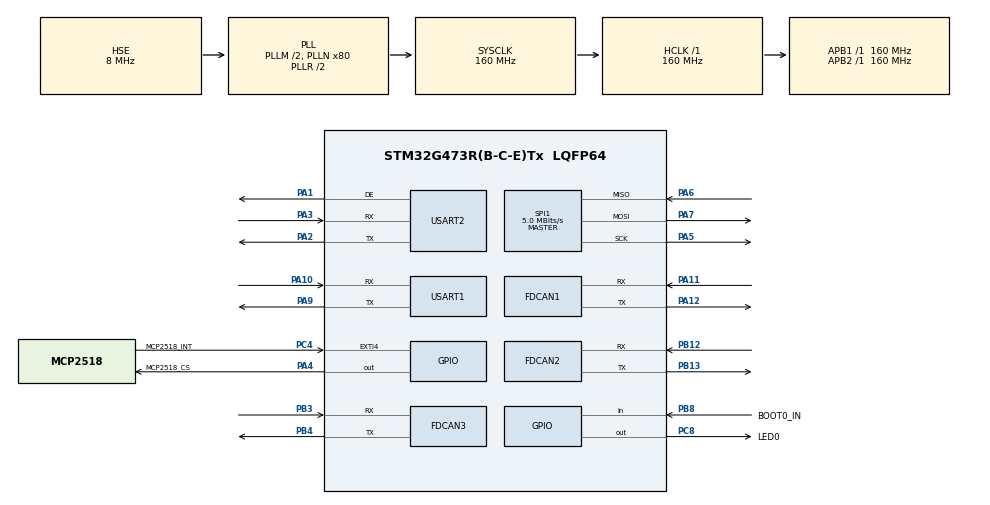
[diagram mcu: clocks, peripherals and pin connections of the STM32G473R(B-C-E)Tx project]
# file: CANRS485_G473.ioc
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FDCAN1.CalculateBaudRateNominal=500000
FDCAN1.CalculateTimeBitNominal=2000
FDCAN1.CalculateTimeQuantumNominal=125.0
FDCAN1.ExtFiltersNbr=1
FDCAN1.NominalPrescaler=5
FDCAN1.NominalSyncJumpWidth=2
FDCAN1.NominalTimeSeg1=13
FDCAN1.NominalTimeSeg2=2
FDCAN1.StdFiltersNbr=1
FDCAN2.CalculateBaudRateNominal=500000
FDCAN2.CalculateTimeBitNominal=2000
FDCAN2.CalculateTimeQuantumNominal=125.0
FDCAN2.ExtFiltersNbr=1
FDCAN2.NominalPrescaler=5
FDCAN2.NominalSyncJumpWidth=2
FDCAN2.NominalTimeSeg1=13
FDCAN2.NominalTimeSeg2=2
FDCAN2.StdFiltersNbr=1
FDCAN3.CalculateBaudRateNominal=250000
FDCAN3.CalculateTimeBitNominal=4000
FDCAN3.CalculateTimeQuantumNominal=250.0
FDCAN3.ExtFiltersNbr=1
FDCAN3.NominalPrescaler=10
FDCAN3.NominalSyncJumpWidth=2
FDCAN3.NominalTimeSeg1=13
FDCAN3.NominalTimeSeg2=2
FDCAN3.StdFiltersNbr=1
Mcu.Family=STM32G4
Mcu.Name=STM32G473R(B-C-E)Tx
Mcu.Package=LQFP64
NVIC.EXTI4_IRQn=true\:1\:0\:true\:false\:true\:true\:true\:true
NVIC.FDCAN1_IT0_IRQn=true\:2\:0\:true\:false\:true\:true\:true\:true
NVIC.FDCAN2_IT0_IRQn=true\:2\:0\:true\:false\:true\:true\:true\:true
NVIC.FDCAN3_IT0_IRQn=true\:2\:0\:true\:false\:true\:true\:true\:true
NVIC.PriorityGroup=NVIC_PRIORITYGROUP_4
NVIC.USART1_IRQn=true\:4\:0\:true\:false\:true\:true\:true\:true
NVIC.USART2_IRQn=true\:3\:0\:true\:false\:true\:true\:true\:true
PA1.Mode=Hardware Flow Control (RS485)
PA1.Signal=USART2_DE
PA10.Mode=Asynchronous
PA10.Signal=USART1_RX
PA11.Mode=FDCAN_Activate
PA11.Signal=FDCAN1_RX
PA12.Mode=FDCAN_Activate
PA12.Signal=FDCAN1_TX
PA13.Mode=Serial_Wire
PA13.Signal=SYS_JTMS-SWDIO
PA14.Mode=Serial_Wire
PA14.Signal=SYS_JTCK-SWCLK
PA2.Mode=Asynchronous
PA2.Signal=USART2_TX
PA3.Mode=Asynchronous
PA3.Signal=USART2_RX
PA4.GPIO_Label=MCP2518_CS
PA4.GPIO_Speed=GPIO_SPEED_FREQ_HIGH
PA4.PinState=GPIO_PIN_SET
PA4.Signal=GPIO_Output
PA5.Mode=Full_Duplex_Master
PA5.Signal=SPI1_SCK
PA6.Mode=Full_Duplex_Master
PA6.Signal=SPI1_MISO
PA7.Mode=Full_Duplex_Master
PA7.Signal=SPI1_MOSI
PA9.Mode=Asynchronous
PA9.Signal=USART1_TX
PB12.Mode=FDCAN_Activate
PB12.Signal=FDCAN2_RX
PB13.Mode=FDCAN_Activate
PB13.Signal=FDCAN2_TX
PB3.Mode=FDCAN_Activate
PB3.Signal=FDCAN3_RX
PB4.Mode=FDCAN_Activate
PB4.Signal=FDCAN3_TX
PB8-BOOT0.GPIO_Label=BOOT0_IN
PB8-BOOT0.Signal=GPIO_Input
PC4.GPIO_Label=MCP2518_INT
PC4.GPIO_ModeDefaultEXTI=GPIO_MODE_IT_FALLING
PC4.Signal=GPXTI4
PC8.GPIO_Label=LED0
PC8.Signal=GPIO_Output
PF0-OSC_IN.Mode=HSE-External-Oscillator
PF0-OSC_IN.Signal=RCC_OSC_IN
PF1-OSC_OUT.Mode=HSE-External-Oscillator
PF1-OSC_OUT.Signal=RCC_OSC_OUT
ProjectManager.HeapSize=0x200
ProjectManager.StackSize=0x400
ProjectManager.TargetToolchain=CMake
RCC.ADC12Freq_Value=160000000
RCC.ADC345Freq_Value=160000000
RCC.AHBFreq_Value=160000000
RCC.APB1Freq_Value=160000000
RCC.APB1TimFreq_Value=160000000
RCC.APB2Freq_Value=160000000
RCC.APB2TimFreq_Value=160000000
RCC.CortexFreq_Value=160000000
RCC.EXTERNAL_CLOCK_VALUE=12288000
RCC.EnbaleCSS=true
RCC.FDCANCLockSelection=RCC_FDCANCLKSOURCE_PLL
RCC.HCLKFreq_Value=160000000
RCC.HSE_VALUE=8000000
RCC.HSI48_VALUE=48000000
RCC.HSI_VALUE=16000000
RCC.LSE_VALUE=32768
RCC.PLLM=RCC_PLLM_DIV2
RCC.PLLN=80
RCC.PLLQ=RCC_PLLQ_DIV8
RCC.PLLSourceVirtual=RCC_PLLSOURCE_HSE
RCC.SYSCLKFreq_VALUE=160000000
RCC.SYSCLKSource=RCC_SYSCLKSOURCE_PLLCLK
RCC.USBFreq_Value=40000000
RCC.VCOOutputFreq_Value=320000000
SPI1.BaudRatePrescaler=SPI_BAUDRATEPRESCALER_32
SPI1.CalculateBaudRate=5.0 MBits/s
SPI1.DataSize=SPI_DATASIZE_8BIT
SPI1.Direction=SPI_DIRECTION_2LINES
SPI1.Mode=SPI_MODE_MASTER
SPI1.VirtualType=VM_MASTER
USART1.VirtualMode-Asynchronous=VM_ASYNC
USART2.VirtualMode-Asynchronous=VM_ASYNC
USART2.VirtualMode-Hardware\ Flow\ Control\ (RS485)=VM_ASYNC
VP_SYS_VS_DBSignals.Mode=DisableDeadBatterySignals
board=custom

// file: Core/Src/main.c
/* USER CODE BEGIN Header */
/**
  ******************************************************************************
  * @file           : main.c
  * @brief          : Main program body
  ******************************************************************************
  * @attention
  *
  * Copyright (c) 2026 STMicroelectronics.
  * All rights reserved.
  *
  * This software is licensed under terms that can be found in the LICENSE file
  * in the root directory of this software component.
  * If no LICENSE file comes with this software, it is provided AS-IS.
  *
  ******************************************************************************
  */
/* USER CODE END Header */
#include "main.h"
#include "fdcan.h"
#include "spi.h"
#include "usart.h"
#include "gpio.h"

/* USER CODE BEGIN Includes */
#include "app.h"

/* USER CODE END Includes */

void SystemClock_Config(void);

int main(void)
{

  /* MCU Configuration--------------------------------------------------------*/

  /* Reset of all peripherals, Initializes the Flash interface and the Systick. */
  HAL_Init();

  /* Configure the system clock */
  SystemClock_Config();

  /* USER CODE BEGIN SysInit */
  HAL_PWREx_DisableUCPDDeadBattery();

  /* USER CODE END SysInit */

  /* Initialize all configured peripherals */
  MX_GPIO_Init();
  MX_FDCAN1_Init();
  MX_FDCAN2_Init();
  MX_FDCAN3_Init();
  MX_SPI1_Init();
  MX_USART1_UART_Init();
  MX_USART2_UART_Init();
  /* USER CODE BEGIN 2 */
  App_Init();

  /* USER CODE END 2 */

  /* Infinite loop */
  while (1)
  {

    /* USER CODE BEGIN 3 */
    App_Run();
  }
  /* USER CODE END 3 */
}

void SystemClock_Config(void)
{
  RCC_OscInitTypeDef RCC_OscInitStruct = {0};
  RCC_ClkInitTypeDef RCC_ClkInitStruct = {0};

  /** Configure the main internal regulator output voltage
  */
  HAL_PWREx_ControlVoltageScaling(PWR_REGULATOR_VOLTAGE_SCALE1_BOOST);

  /** Initializes the RCC Oscillators according to the specified parameters
  * in the RCC_OscInitTypeDef structure.
  */
  RCC_OscInitStruct.OscillatorType = RCC_OSCILLATORTYPE_HSE;
  RCC_OscInitStruct.HSEState = RCC_HSE_ON;
  RCC_OscInitStruct.PLL.PLLState = RCC_PLL_ON;
  RCC_OscInitStruct.PLL.PLLSource = RCC_PLLSOURCE_HSE;
  RCC_OscInitStruct.PLL.PLLM = RCC_PLLM_DIV2;
  RCC_OscInitStruct.PLL.PLLN = 80;
  RCC_OscInitStruct.PLL.PLLP = RCC_PLLP_DIV2;
  RCC_OscInitStruct.PLL.PLLQ = RCC_PLLQ_DIV8;
  RCC_OscInitStruct.PLL.PLLR = RCC_PLLR_DIV2;
  if (HAL_RCC_OscConfig(&RCC_OscInitStruct) != HAL_OK)
  {
    Error_Handler();
  }

  /** Initializes the CPU, AHB and APB buses clocks
  */
  RCC_ClkInitStruct.ClockType = RCC_CLOCKTYPE_HCLK|RCC_CLOCKTYPE_SYSCLK
                              |RCC_CLOCKTYPE_PCLK1|RCC_CLOCKTYPE_PCLK2;
  RCC_ClkInitStruct.SYSCLKSource = RCC_SYSCLKSOURCE_PLLCLK;
  RCC_ClkInitStruct.AHBCLKDivider = RCC_SYSCLK_DIV1;
  RCC_ClkInitStruct.APB1CLKDivider = RCC_HCLK_DIV1;
  RCC_ClkInitStruct.APB2CLKDivider = RCC_HCLK_DIV1;

  if (HAL_RCC_ClockConfig(&RCC_ClkInitStruct, FLASH_LATENCY_4) != HAL_OK)
  {
    Error_Handler();
  }

  /** Enables the Clock Security System
  */
  HAL_RCC_EnableCSS();
}

void Error_Handler(void)
{
  __disable_irq();
  while (1)
  {
  }
}
